AUTOSAR XML (schema 4-2-2)
package /MICROSAR_SWCS_DEV/IoHwAb_swc/ComponentTypes
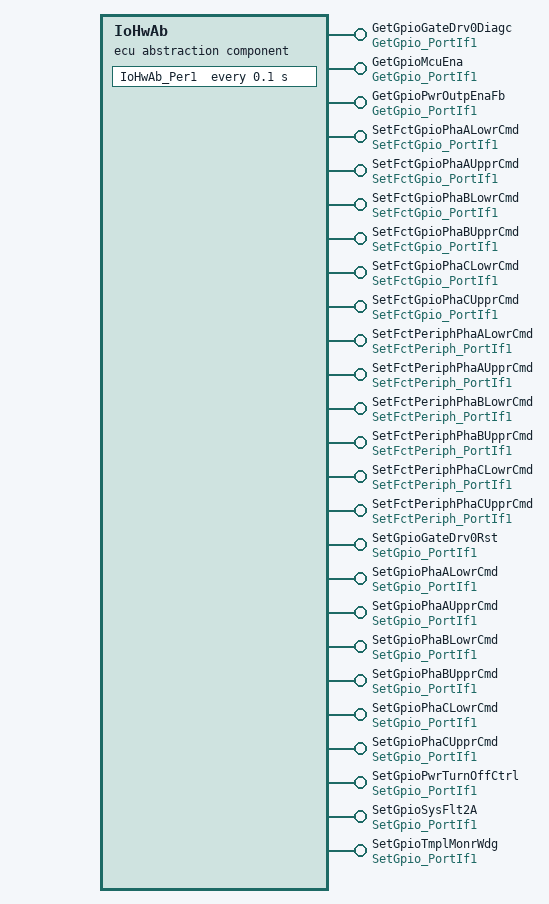
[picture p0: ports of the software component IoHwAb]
  ecu abstraction sw component type IoHwAb
    25 x provide port, all with server-com-spec{operation=Oper, queue-length=1}:
      GetGpioGateDrv0Diagc: provided-interface=GetGpio_PortIf1
      GetGpioMcuEna: provided-interface=GetGpio_PortIf1
      GetGpioPwrOutpEnaFb: provided-interface=GetGpio_PortIf1
      SetFctGpioPhaALowrCmd: provided-interface=SetFctGpio_PortIf1
      SetFctGpioPhaAUpprCmd: provided-interface=SetFctGpio_PortIf1
      SetFctGpioPhaBLowrCmd: provided-interface=SetFctGpio_PortIf1
      SetFctGpioPhaBUpprCmd: provided-interface=SetFctGpio_PortIf1
      SetFctGpioPhaCLowrCmd: provided-interface=SetFctGpio_PortIf1
      SetFctGpioPhaCUpprCmd: provided-interface=SetFctGpio_PortIf1
      SetFctPeriphPhaALowrCmd: provided-interface=SetFctPeriph_PortIf1
      SetFctPeriphPhaAUpprCmd: provided-interface=SetFctPeriph_PortIf1
      SetFctPeriphPhaBLowrCmd: provided-interface=SetFctPeriph_PortIf1
      SetFctPeriphPhaBUpprCmd: provided-interface=SetFctPeriph_PortIf1
      SetFctPeriphPhaCLowrCmd: provided-interface=SetFctPeriph_PortIf1
      SetFctPeriphPhaCUpprCmd: provided-interface=SetFctPeriph_PortIf1
      SetGpioGateDrv0Rst: provided-interface=SetGpio_PortIf1
      SetGpioPhaALowrCmd: provided-interface=SetGpio_PortIf1
      SetGpioPhaAUpprCmd: provided-interface=SetGpio_PortIf1
      SetGpioPhaBLowrCmd: provided-interface=SetGpio_PortIf1
      SetGpioPhaBUpprCmd: provided-interface=SetGpio_PortIf1
      SetGpioPhaCLowrCmd: provided-interface=SetGpio_PortIf1
      SetGpioPhaCUpprCmd: provided-interface=SetGpio_PortIf1
      SetGpioPwrTurnOffCtrl: provided-interface=SetGpio_PortIf1
      SetGpioSysFlt2A: provided-interface=SetGpio_PortIf1
      SetGpioTmplMonrWdg: provided-interface=SetGpio_PortIf1
    behavior IoHwAbInternalBehavior
      operation invoked event OpEventIoHwAb_GetGpioGateDrv0Diagc_Oper_Oper_GetGpioGateDrv0Diagc: start-on-event=IoHwAb_GetGpioGateDrv0Diagc_Oper, operation=GetGpioGateDrv0Diagc.Oper
      operation invoked event OpEventIoHwAb_GetGpioMcuEna_Oper_Oper_GetGpioMcuEna: start-on-event=IoHwAb_GetGpioMcuEna_Oper, operation=GetGpioMcuEna.Oper
      operation invoked event OpEventIoHwAb_GetGpioPwrOutpEnaFb_Oper_Oper_GetGpioPwrOutpEnaFb: start-on-event=IoHwAb_GetGpioPwrOutpEnaFb_Oper, operation=GetGpioPwrOutpEnaFb.Oper
      timing event Timer_IoHwAb_Per1: start-on-event=IoHwAb_Per1, period=0.1
      22 x operation invoked event:
        OpEventIoHwAb_SetFctGpioPhaALowrCmd_Oper_Oper_SetFctGpioPhaALowrCmd: start-on-event=IoHwAb_SetFctGpioPhaALowrCmd_Oper, operation=SetFctGpioPhaALowrCmd.Oper
        OpEventIoHwAb_SetFctGpioPhaAUpprCmd_Oper_Oper_SetFctGpioPhaAUpprCmd: start-on-event=IoHwAb_SetFctGpioPhaAUpprCmd_Oper, operation=SetFctGpioPhaAUpprCmd.Oper
        OpEventIoHwAb_SetFctGpioPhaBLowrCmd_Oper_Oper_SetFctGpioPhaBLowrCmd: start-on-event=IoHwAb_SetFctGpioPhaBLowrCmd_Oper, operation=SetFctGpioPhaBLowrCmd.Oper
        OpEventIoHwAb_SetFctGpioPhaBUpprCmd_Oper_Oper_SetFctGpioPhaBUpprCmd: start-on-event=IoHwAb_SetFctGpioPhaBUpprCmd_Oper, operation=SetFctGpioPhaBUpprCmd.Oper
        OpEventIoHwAb_SetFctGpioPhaCLowrCmd_Oper_Oper_SetFctGpioPhaCLowrCmd: start-on-event=IoHwAb_SetFctGpioPhaCLowrCmd_Oper, operation=SetFctGpioPhaCLowrCmd.Oper
        OpEventIoHwAb_SetFctGpioPhaCUpprCmd_Oper_Oper_SetFctGpioPhaCUpprCmd: start-on-event=IoHwAb_SetFctGpioPhaCUpprCmd_Oper, operation=SetFctGpioPhaCUpprCmd.Oper
        OpEventIoHwAb_SetFctPeriphPhaALowrCmd_Oper_Oper_SetFctPeriphPhaALowrCmd: start-on-event=IoHwAb_SetFctPeriphPhaALowrCmd_Oper, operation=SetFctPeriphPhaALowrCmd.Oper
        OpEventIoHwAb_SetFctPeriphPhaAUpprCmd_Oper_Oper_SetFctPeriphPhaAUpprCmd: start-on-event=IoHwAb_SetFctPeriphPhaAUpprCmd_Oper, operation=SetFctPeriphPhaAUpprCmd.Oper
        OpEventIoHwAb_SetFctPeriphPhaBLowrCmd_Oper_Oper_SetFctPeriphPhaBLowrCmd: start-on-event=IoHwAb_SetFctPeriphPhaBLowrCmd_Oper, operation=SetFctPeriphPhaBLowrCmd.Oper
        OpEventIoHwAb_SetFctPeriphPhaBUpprCmd_Oper_Oper_SetFctPeriphPhaBUpprCmd: start-on-event=IoHwAb_SetFctPeriphPhaBUpprCmd_Oper, operation=SetFctPeriphPhaBUpprCmd.Oper
        OpEventIoHwAb_SetFctPeriphPhaCLowrCmd_Oper_Oper_SetFctPeriphPhaCLowrCmd: start-on-event=IoHwAb_SetFctPeriphPhaCLowrCmd_Oper, operation=SetFctPeriphPhaCLowrCmd.Oper
        OpEventIoHwAb_SetFctPeriphPhaCUpprCmd_Oper_Oper_SetFctPeriphPhaCUpprCmd: start-on-event=IoHwAb_SetFctPeriphPhaCUpprCmd_Oper, operation=SetFctPeriphPhaCUpprCmd.Oper
        OpEventIoHwAb_SetGpioGateDrv0Rst_Oper_Oper_SetGpioGateDrv0Rst: start-on-event=IoHwAb_SetGpioGateDrv0Rst_Oper, operation=SetGpioGateDrv0Rst.Oper
        OpEventIoHwAb_SetGpioPhaALowrCmd_Oper_Oper_SetGpioPhaALowrCmd: start-on-event=IoHwAb_SetGpioPhaALowrCmd_Oper, operation=SetGpioPhaALowrCmd.Oper
        OpEventIoHwAb_SetGpioPhaAUpprCmd_Oper_Oper_SetGpioPhaAUpprCmd: start-on-event=IoHwAb_SetGpioPhaAUpprCmd_Oper, operation=SetGpioPhaAUpprCmd.Oper
        OpEventIoHwAb_SetGpioPhaBLowrCmd_Oper_Oper_SetGpioPhaBLowrCmd: start-on-event=IoHwAb_SetGpioPhaBLowrCmd_Oper, operation=SetGpioPhaBLowrCmd.Oper
        OpEventIoHwAb_SetGpioPhaBUpprCmd_Oper_Oper_SetGpioPhaBUpprCmd: start-on-event=IoHwAb_SetGpioPhaBUpprCmd_Oper, operation=SetGpioPhaBUpprCmd.Oper
        OpEventIoHwAb_SetGpioPhaCLowrCmd_Oper_Oper_SetGpioPhaCLowrCmd: start-on-event=IoHwAb_SetGpioPhaCLowrCmd_Oper, operation=SetGpioPhaCLowrCmd.Oper
        OpEventIoHwAb_SetGpioPhaCUpprCmd_Oper_Oper_SetGpioPhaCUpprCmd: start-on-event=IoHwAb_SetGpioPhaCUpprCmd_Oper, operation=SetGpioPhaCUpprCmd.Oper
        OpEventIoHwAb_SetGpioPwrTurnOffCtrl_Oper_Oper_SetGpioPwrTurnOffCtrl: start-on-event=IoHwAb_SetGpioPwrTurnOffCtrl_Oper, operation=SetGpioPwrTurnOffCtrl.Oper
        OpEventIoHwAb_SetGpioSysFlt2A_Oper_Oper_SetGpioSysFlt2A: start-on-event=IoHwAb_SetGpioSysFlt2A_Oper, operation=SetGpioSysFlt2A.Oper
        OpEventIoHwAb_SetGpioTmplMonrWdg_Oper_Oper_SetGpioTmplMonrWdg: start-on-event=IoHwAb_SetGpioTmplMonrWdg_Oper, operation=SetGpioTmplMonrWdg.Oper
      port-api-options:
        enable-take-address=true, error-handling=NO-TRANSFORMER-ERROR-HANDLING, indirect-api=false, port=GetGpioGateDrv0Diagc
        enable-take-address=true, error-handling=NO-TRANSFORMER-ERROR-HANDLING, indirect-api=false, port=GetGpioMcuEna
        enable-take-address=true, error-handling=NO-TRANSFORMER-ERROR-HANDLING, indirect-api=false, port=GetGpioPwrOutpEnaFb
        enable-take-address=true, error-handling=NO-TRANSFORMER-ERROR-HANDLING, indirect-api=false, port=SetFctGpioPhaALowrCmd
        enable-take-address=true, error-handling=NO-TRANSFORMER-ERROR-HANDLING, indirect-api=false, port=SetFctGpioPhaAUpprCmd
        enable-take-address=true, error-handling=NO-TRANSFORMER-ERROR-HANDLING, indirect-api=false, port=SetFctGpioPhaBLowrCmd
        enable-take-address=true, error-handling=NO-TRANSFORMER-ERROR-HANDLING, indirect-api=false, port=SetFctGpioPhaBUpprCmd
        enable-take-address=true, error-handling=NO-TRANSFORMER-ERROR-HANDLING, indirect-api=false, port=SetFctGpioPhaCLowrCmd
        enable-take-address=true, error-handling=NO-TRANSFORMER-ERROR-HANDLING, indirect-api=false, port=SetFctGpioPhaCUpprCmd
        enable-take-address=true, error-handling=NO-TRANSFORMER-ERROR-HANDLING, indirect-api=false, port=SetFctPeriphPhaALowrCmd
        enable-take-address=true, error-handling=NO-TRANSFORMER-ERROR-HANDLING, indirect-api=false, port=SetFctPeriphPhaAUpprCmd
        enable-take-address=true, error-handling=NO-TRANSFORMER-ERROR-HANDLING, indirect-api=false, port=SetFctPeriphPhaBLowrCmd
        enable-take-address=true, error-handling=NO-TRANSFORMER-ERROR-HANDLING, indirect-api=false, port=SetFctPeriphPhaBUpprCmd
        enable-take-address=true, error-handling=NO-TRANSFORMER-ERROR-HANDLING, indirect-api=false, port=SetFctPeriphPhaCLowrCmd
        enable-take-address=true, error-handling=NO-TRANSFORMER-ERROR-HANDLING, indirect-api=false, port=SetFctPeriphPhaCUpprCmd
        enable-take-address=true, error-handling=NO-TRANSFORMER-ERROR-HANDLING, indirect-api=false, port=SetGpioGateDrv0Rst
        enable-take-address=true, error-handling=NO-TRANSFORMER-ERROR-HANDLING, indirect-api=false, port=SetGpioPhaALowrCmd
        enable-take-address=true, error-handling=NO-TRANSFORMER-ERROR-HANDLING, indirect-api=false, port=SetGpioPhaAUpprCmd
        enable-take-address=true, error-handling=NO-TRANSFORMER-ERROR-HANDLING, indirect-api=false, port=SetGpioPhaBLowrCmd
        enable-take-address=true, error-handling=NO-TRANSFORMER-ERROR-HANDLING, indirect-api=false, port=SetGpioPhaBUpprCmd
        enable-take-address=true, error-handling=NO-TRANSFORMER-ERROR-HANDLING, indirect-api=false, port=SetGpioPhaCLowrCmd
        enable-take-address=true, error-handling=NO-TRANSFORMER-ERROR-HANDLING, indirect-api=false, port=SetGpioPhaCUpprCmd
        enable-take-address=true, error-handling=NO-TRANSFORMER-ERROR-HANDLING, indirect-api=false, port=SetGpioPwrTurnOffCtrl
        enable-take-address=true, error-handling=NO-TRANSFORMER-ERROR-HANDLING, indirect-api=false, port=SetGpioSysFlt2A
        enable-take-address=true, error-handling=NO-TRANSFORMER-ERROR-HANDLING, indirect-api=false, port=SetGpioTmplMonrWdg
      26 x runnable, all with can-be-invoked-concurrently=true:
        IoHwAb_GetGpioGateDrv0Diagc_Oper  # Runnable Entity for calling the Operation 'Oper' of the Client/Server Port Prototype 'GetGpioGateDrv0Diagc'.
        IoHwAb_GetGpioMcuEna_Oper  # Runnable Entity for calling the Operation 'Oper' of the Client/Server Port Prototype 'GetGpioMcuEna'.
        IoHwAb_GetGpioPwrOutpEnaFb_Oper  # Runnable Entity for calling the Operation 'Oper' of the Client/Server Port Prototype 'GetGpioPwrOutpEnaFb'.
        IoHwAb_Per1
        IoHwAb_SetFctGpioPhaALowrCmd_Oper  # Runnable Entity for calling the Operation 'Oper' of the Client/Server Port Prototype 'SetFctGpioPhaALowrCmd'.
        IoHwAb_SetFctGpioPhaAUpprCmd_Oper  # Runnable Entity for calling the Operation 'Oper' of the Client/Server Port Prototype 'SetFctGpioPhaAUpprCmd'.
        IoHwAb_SetFctGpioPhaBLowrCmd_Oper  # Runnable Entity for calling the Operation 'Oper' of the Client/Server Port Prototype 'SetFctGpioPhaBLowrCmd'.
        IoHwAb_SetFctGpioPhaBUpprCmd_Oper  # Runnable Entity for calling the Operation 'Oper' of the Client/Server Port Prototype 'SetFctGpioPhaBUpprCmd'.
        IoHwAb_SetFctGpioPhaCLowrCmd_Oper  # Runnable Entity for calling the Operation 'Oper' of the Client/Server Port Prototype 'SetFctGpioPhaCLowrCmd'.
        IoHwAb_SetFctGpioPhaCUpprCmd_Oper  # Runnable Entity for calling the Operation 'Oper' of the Client/Server Port Prototype 'SetFctGpioPhaCUpprCmd'.
        IoHwAb_SetFctPeriphPhaALowrCmd_Oper  # Runnable Entity for calling the Operation 'Oper' of the Client/Server Port Prototype 'SetFctPeriphPhaALowrCmd'.
        IoHwAb_SetFctPeriphPhaAUpprCmd_Oper  # Runnable Entity for calling the Operation 'Oper' of the Client/Server Port Prototype 'SetFctPeriphPhaAUpprCmd'.
        IoHwAb_SetFctPeriphPhaBLowrCmd_Oper  # Runnable Entity for calling the Operation 'Oper' of the Client/Server Port Prototype 'SetFctPeriphPhaBLowrCmd'.
        IoHwAb_SetFctPeriphPhaBUpprCmd_Oper  # Runnable Entity for calling the Operation 'Oper' of the Client/Server Port Prototype 'SetFctPeriphPhaBUpprCmd'.
        IoHwAb_SetFctPeriphPhaCLowrCmd_Oper  # Runnable Entity for calling the Operation 'Oper' of the Client/Server Port Prototype 'SetFctPeriphPhaCLowrCmd'.
        IoHwAb_SetFctPeriphPhaCUpprCmd_Oper  # Runnable Entity for calling the Operation 'Oper' of the Client/Server Port Prototype 'SetFctPeriphPhaCUpprCmd'.
        IoHwAb_SetGpioGateDrv0Rst_Oper  # Runnable Entity for calling the Operation 'Oper' of the Client/Server Port Prototype 'SetGpioGateDrv0Rst'.
        IoHwAb_SetGpioPhaALowrCmd_Oper  # Runnable Entity for calling the Operation 'Oper' of the Client/Server Port Prototype 'SetGpioPhaALowrCmd'.
        IoHwAb_SetGpioPhaAUpprCmd_Oper  # Runnable Entity for calling the Operation 'Oper' of the Client/Server Port Prototype 'SetGpioPhaAUpprCmd'.
        IoHwAb_SetGpioPhaBLowrCmd_Oper  # Runnable Entity for calling the Operation 'Oper' of the Client/Server Port Prototype 'SetGpioPhaBLowrCmd'.
        IoHwAb_SetGpioPhaBUpprCmd_Oper  # Runnable Entity for calling the Operation 'Oper' of the Client/Server Port Prototype 'SetGpioPhaBUpprCmd'.
        IoHwAb_SetGpioPhaCLowrCmd_Oper  # Runnable Entity for calling the Operation 'Oper' of the Client/Server Port Prototype 'SetGpioPhaCLowrCmd'.
        IoHwAb_SetGpioPhaCUpprCmd_Oper  # Runnable Entity for calling the Operation 'Oper' of the Client/Server Port Prototype 'SetGpioPhaCUpprCmd'.
        IoHwAb_SetGpioPwrTurnOffCtrl_Oper  # Runnable Entity for calling the Operation 'Oper' of the Client/Server Port Prototype 'SetGpioPwrTurnOffCtrl'.
        IoHwAb_SetGpioSysFlt2A_Oper  # Runnable Entity for calling the Operation 'Oper' of the Client/Server Port Prototype 'SetGpioSysFlt2A'.
        IoHwAb_SetGpioTmplMonrWdg_Oper  # Runnable Entity for calling the Operation 'Oper' of the Client/Server Port Prototype 'SetGpioTmplMonrWdg'.
  swc implementation IoHwAbImplementation: behavior=IoHwAbInternalBehavior
    code-descriptors:
      code Default: artifact-descriptors=autosar-engineering-object={short-label=Default, category=SWSRC}
